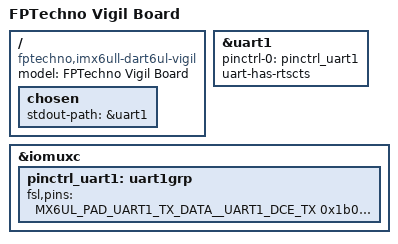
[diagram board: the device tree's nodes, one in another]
/*
 * Copyright (C) 2018 Amotus Solutions, Inc.
 */

/dts-v1/;

#include "imx6ull-dart6ul.dtsi"
#include "imx6ull-dart6ul-emmc-wifi.dtsi"
#include "imx6ull-dart6ul-audio.dtsi"
#include "imx6ull-dart6ul-ethernet.dtsi"

/ {
	model = "FPTechno Vigil Board";
	compatible = "fptechno,imx6ull-dart6ul-vigil", "fsl,imx6ull";

	chosen {
		stdout-path = &uart1;
	};
};

/* debug uart */
&uart1 {
	pinctrl-names = "default";
	pinctrl-0 = <&pinctrl_uart1>;
	uart-has-rtscts;
	status = "okay";
};

&iomuxc {
	pinctrl_uart1: uart1grp {
		fsl,pins = <
		MX6UL_PAD_UART1_TX_DATA__UART1_DCE_TX	0x1b0b1
		MX6UL_PAD_UART1_RX_DATA__UART1_DCE_RX	0x1b0b1
		MX6UL_PAD_UART1_CTS_B__UART1_DCE_CTS	0x1b0b1
		MX6UL_PAD_UART1_RTS_B__UART1_DCE_RTS	0x1b0b1
		>;
	};
};
